# STM32G0C1 register map
File version: 1.8
CPU: CM0 r0p1, little endian, MPU, no FPU, 2 interrupt priority bits
Registers are 32-bit, read-write, reset 0x0 unless marked. A register's access mark holds for its fields unless they carry their own. Offsets are from the block's base; [hi:lo] are bit positions; {n}, {i} and the like mark numbered series; 'fields as' and 'values as' point back to an identical list.

## EXTI — External interrupt/event controller
Base 0x40021800
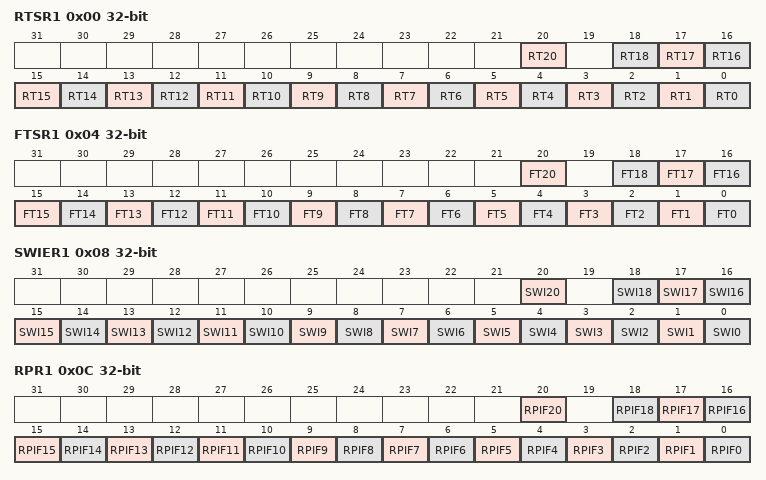
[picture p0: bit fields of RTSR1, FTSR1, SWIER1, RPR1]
0x00 RTSR1 — EXTI rising trigger selection register
  [all] fields
    0=Disabled (Rising edge trigger is disabled); 1=Enabled (Rising edge trigger is enabled)
  [20] RT20 — Rising trigger event configuration bit of Configurable Event line
  [n] RT{n} (n=0..18) — Rising trigger event configuration bit of Configurable Event line
0x04 FTSR1 — EXTI falling trigger selection register
  [all] fields
    0=Disabled (Falling edge trigger is disabled); 1=Enabled (Falling edge trigger is enabled)
  [20] FT20 — Rising trigger event configuration bit of Configurable Event input
  [n] FT{n} (n=0..18) — Falling trigger event configuration bit of configurable line
0x08 SWIER1 — EXTI software interrupt event register
  [all] fields
    on write: 1=Pend (Generates an interrupt request)
  [20] SWI20 — Software rising edge event trigger on line
  [n] SWI{n} (n=0..18) — Software rising edge event trigger on line
0x0C RPR1 — EXTI rising edge pending register
  [all] fields
    on read: 0=NotPending (No trigger request occurred); 1=Pending (Selected trigger request occurred) | on write: 1=Clears pending bit
  [20] RPIF20 write-1-clears — Rising edge event pending for configurable line
  [n] RPIF{n} write-1-clears (n=6..18) — Rising edge event pending for configurable line
  [5] RPIF5 write-1-clears — configurable event inputs x rising edge Pending bit
  [n] RPIF{n} write-1-clears (n=0..4) — Rising edge event pending for configurable line
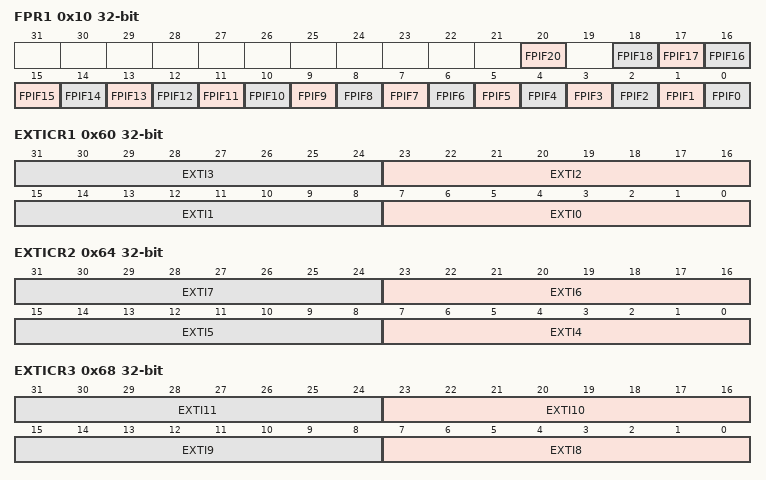
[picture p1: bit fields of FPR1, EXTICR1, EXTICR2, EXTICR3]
0x10 FPR1 — EXTI falling edge pending register
  [all] fields
    values as the fields of RPR1
  [20] FPIF20 write-1-clears — Falling edge event pending for configurable line
  [n] FPIF{n} write-1-clears (n=0..18) — Falling edge event pending for configurable line
0x28 RTSR2 — EXTI rising trigger selection register 2
  [2] RT2 — Rising trigger event configuration bit of configurable line 34
    values as the fields of RTSR1
0x2C FTSR2 — EXTI falling trigger selection register 2
  [2] FT2 — Falling trigger event configuration bit of configurable line 34
    values as the fields of FTSR1
0x30 SWIER2 — EXTI software interrupt event register 2
  [2] SWI2 — Software rising edge event trigger on line 34
    on write: 1=Pend (Generates an interrupt request)
0x34 RPR2 — EXTI rising edge pending register 2
  [2] RPIF2 write-1-clears — Rising edge event pending for configurable line 34
    values as the fields of RPR1
0x38 FPR2 — EXTI falling edge pending register 2
  [2] FPIF2 write-1-clears — Falling edge event pending for configurable line 34
    values as the fields of RPR1
0x60 EXTICR1 — EXTI external interrupt selection register
  [all] fields
    0=PA (Select PAx as the source input for the EXTIx external interrupt); 1=PB (Select PBx as the source input for the EXTIx external interrupt); 2=PC (Select PCx as the source input for the EXTIx external interrupt); 3=PD (Select PDx as the source input for the EXTIx external interrupt); 5=PF (Select PFx as the source input for the EXTIx external interrupt)
  [8n+7:8n] EXTI{n} (n=0..3) — GPIO port selection
0x64 EXTICR2 — EXTI external interrupt selection register
  [all] fields
    values as the fields of EXTICR1
  [8n-25:8n-32] EXTI{n} (n=4..7) — GPIO port selection
0x68 EXTICR3 — EXTI external interrupt selection register
  [all] fields
    values as the fields of EXTICR1
  [8n-57:8n-64] EXTI{n} (n=8..11) — GPIO port selection
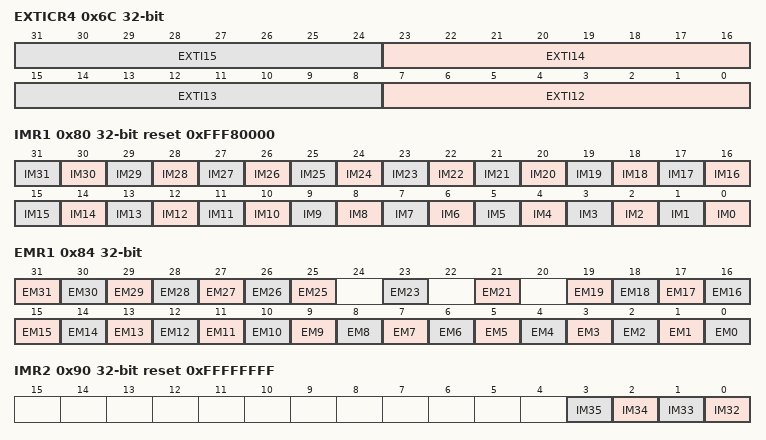
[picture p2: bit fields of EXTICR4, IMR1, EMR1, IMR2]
0x6C EXTICR4 — EXTI external interrupt selection register
  [all] fields
    values as the fields of EXTICR1
  [8n-89:8n-96] EXTI{n} (n=12..15) — GPIO port selection
0x80 IMR1 reset 0xFFF80000 — EXTI CPU wakeup with interrupt mask register
  [all] fields
    0=Masked (Interrupt request line is masked); 1=Unmasked (Interrupt request line is unmasked)
  [n] IM{n} (n=0..31) — CPU wakeup with interrupt mask on event input
0x84 EMR1 (alternate view of IMR1) — EXTI CPU wakeup with event mask register
  [all] fields
    0=Masked (Event request line is masked); 1=Unmasked (Event request line is unmasked)
  [n] EM{n} (n=25..31) — CPU wakeup with event mask on event input
  [23] EM23 — CPU wakeup with event mask on event input
  [21] EM21 — CPU wakeup with event mask on event input
  [n] EM{n} (n=0..19) — CPU wakeup with event mask on event input
0x90 IMR2 reset 0xFFFFFFFF — EXTI CPU wakeup with interrupt mask register
  [all] fields
    values as the fields of IMR1
  [n-32] IM{n} (n=32..35) — CPU wakeup with interrupt mask on event input
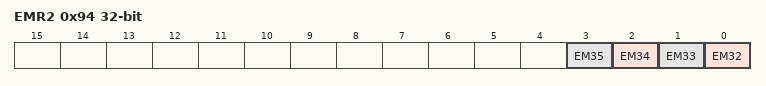
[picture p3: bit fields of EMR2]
0x94 EMR2 — EXTI CPU wakeup with event mask register
  [all] fields
    values as the fields of EMR1
  [n-32] EM{n} (n=32..35) — CPU wakeup with event mask on event input
